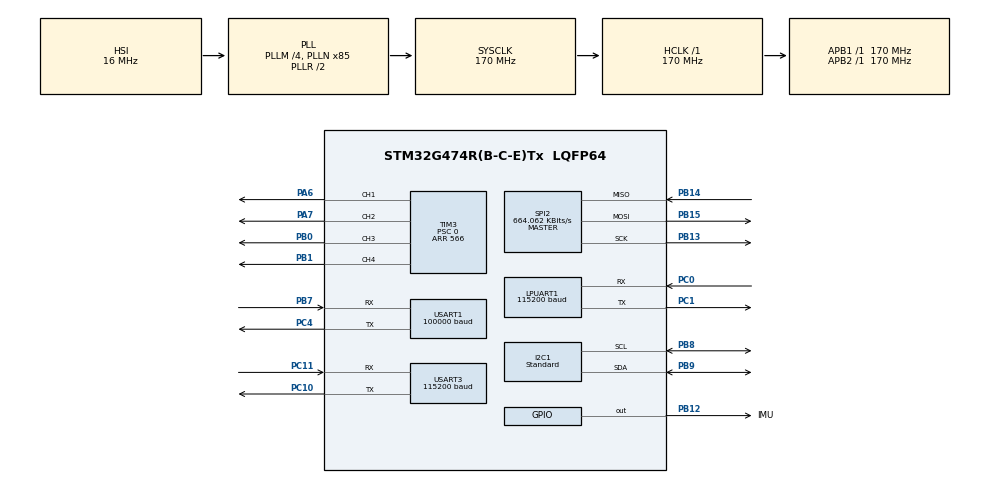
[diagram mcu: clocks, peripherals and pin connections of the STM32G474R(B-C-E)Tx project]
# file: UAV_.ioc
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Dma.Request0=TIM3_UP
Dma.TIM3_UP.0.Direction=DMA_MEMORY_TO_PERIPH
Dma.TIM3_UP.0.EventEnable=DISABLE
Dma.TIM3_UP.0.Instance=DMA1_Channel1
Dma.TIM3_UP.0.MemDataAlignment=DMA_MDATAALIGN_HALFWORD
Dma.TIM3_UP.0.MemInc=DMA_MINC_ENABLE
Dma.TIM3_UP.0.Mode=DMA_NORMAL
Dma.TIM3_UP.0.PeriphDataAlignment=DMA_PDATAALIGN_HALFWORD
Dma.TIM3_UP.0.PeriphInc=DMA_PINC_DISABLE
Dma.TIM3_UP.0.Polarity=HAL_DMAMUX_REQ_GEN_RISING
Dma.TIM3_UP.0.Priority=DMA_PRIORITY_VERY_HIGH
Dma.TIM3_UP.0.RequestNumber=1
Dma.TIM3_UP.0.SignalID=NONE
Dma.TIM3_UP.0.SyncEnable=DISABLE
Dma.TIM3_UP.0.SyncPolarity=HAL_DMAMUX_SYNC_NO_EVENT
Dma.TIM3_UP.0.SyncRequestNumber=1
Dma.TIM3_UP.0.SyncSignalID=NONE
I2C1.I2C_Speed_Mode=I2C_Standard
I2C1.Timing=0x40B285C2
LPUART1.BaudRate=115200
Mcu.Family=STM32G4
Mcu.Name=STM32G474R(B-C-E)Tx
Mcu.Package=LQFP64
NUCLEO-G474RE.BUTTON=1
NUCLEO-G474RE.LD2=true
NUCLEO-G474RE.VCP=false
NVIC.DMA1_Channel1_IRQn=true\:0\:0\:false\:false\:true\:false\:true\:true
NVIC.EXTI15_10_IRQn=true\:0\:0\:false\:false\:true\:false\:true\:true
NVIC.I2C1_ER_IRQn=true\:4\:0\:false\:false\:true\:true\:true\:true
NVIC.I2C1_EV_IRQn=true\:4\:0\:false\:false\:true\:true\:true\:true
NVIC.LPUART1_IRQn=true\:6\:0\:false\:false\:true\:true\:true\:true
NVIC.PriorityGroup=NVIC_PRIORITYGROUP_4
NVIC.TIM3_IRQn=true\:0\:0\:false\:false\:true\:true\:true\:true
NVIC.USART1_IRQn=true\:2\:0\:false\:false\:true\:true\:true\:true
NVIC.USART3_IRQn=true\:3\:0\:false\:false\:true\:true\:true\:true
PA13.Mode=Serial_Wire
PA13.Signal=SYS_JTMS-SWDIO
PA14.Mode=Serial_Wire
PA14.Signal=SYS_JTCK-SWCLK
PC1.Mode=Asynchronous
PC1.Signal=LPUART1_TX
PC0.Mode=Asynchronous
PC0.Signal=LPUART1_RX
PA7.Signal=S_TIM3_CH2
PA6.Signal=S_TIM3_CH1
PB0.Signal=S_TIM3_CH3
PB1.Signal=S_TIM3_CH4
PB12.GPIO_Label=IMU
PB12.GPIO_Speed=GPIO_SPEED_FREQ_VERY_HIGH
PB12.PinState=GPIO_PIN_SET
PB12.Signal=GPIO_Output
PB13.Mode=Full_Duplex_Master
PB13.Signal=SPI2_SCK
PB14.Mode=Full_Duplex_Master
PB14.Signal=SPI2_MISO
PB15.Mode=Full_Duplex_Master
PB15.Signal=SPI2_MOSI
PB7.Mode=Asynchronous
PB7.Signal=USART1_RX
PB8-BOOT0.Mode=I2C
PB8-BOOT0.Signal=I2C1_SCL
PB9.Mode=I2C
PB9.Signal=I2C1_SDA
PC4.Mode=Asynchronous
PC4.Signal=USART1_TX
PC10.Mode=Asynchronous
PC10.Signal=USART3_TX
PC11.Mode=Asynchronous
PC11.Signal=USART3_RX
ProjectManager.HeapSize=0x200
ProjectManager.StackSize=0x400
ProjectManager.TargetToolchain=STM32CubeIDE
RCC.ADC12Freq_Value=170000000
RCC.ADC345Freq_Value=170000000
RCC.AHBFreq_Value=170000000
RCC.APB1Freq_Value=170000000
RCC.APB1TimFreq_Value=170000000
RCC.APB2Freq_Value=170000000
RCC.APB2TimFreq_Value=170000000
RCC.CortexFreq_Value=170000000
RCC.EXTERNAL_CLOCK_VALUE=12288000
RCC.HCLKFreq_Value=170000000
RCC.HSE_VALUE=24000000
RCC.HSI48_VALUE=48000000
RCC.HSI_VALUE=16000000
RCC.LSE_VALUE=32768
RCC.PLLM=RCC_PLLM_DIV4
RCC.PLLN=85
RCC.RTCClockSelection=RCC_RTCCLKSOURCE_LSE
RCC.SYSCLKFreq_VALUE=170000000
RCC.SYSCLKSource=RCC_SYSCLKSOURCE_PLLCLK
RCC.USBFreq_Value=170000000
RCC.VCOOutputFreq_Value=340000000
SH.S_TIM3_CH1.0=TIM3_CH1,PWM Generation1 CH1
SH.S_TIM3_CH2.0=TIM3_CH2,PWM Generation2 CH2
SH.S_TIM3_CH3.0=TIM3_CH3,PWM Generation3 CH3
SH.S_TIM3_CH4.0=TIM3_CH4,PWM Generation4 CH4
SPI2.BaudRatePrescaler=SPI_BAUDRATEPRESCALER_256
SPI2.CLKPhase=SPI_PHASE_2EDGE
SPI2.CLKPolarity=SPI_POLARITY_HIGH
SPI2.CalculateBaudRate=664.062 KBits/s
SPI2.DataSize=SPI_DATASIZE_8BIT
SPI2.Direction=SPI_DIRECTION_2LINES
SPI2.Mode=SPI_MODE_MASTER
SPI2.VirtualType=VM_MASTER
TIM3.Channel-PWM\ Generation1\ CH1=TIM_CHANNEL_1
TIM3.Channel-PWM\ Generation2\ CH2=TIM_CHANNEL_2
TIM3.Channel-PWM\ Generation3\ CH3=TIM_CHANNEL_3
TIM3.Channel-PWM\ Generation4\ CH4=TIM_CHANNEL_4
TIM3.PeriodNoDither=566
TIM3.Prescaler=0
USART1.BaudRate=100000
USART1.WordLength=WORDLENGTH_9B
USART1.Parity=PARITY_EVEN
USART1.StopBits=STOPBITS_2
USART1.Mode=MODE_RX
USART1.OverSampling=UART_OVERSAMPLING_16
USART1.HwFlowCtl-Asynchronous=UART_HWCONTROL_NONE
USART1.RxPinLevelInvertParam=ADVFEATURE_RXINV_ENABLE
USART1.VirtualMode-Asynchronous=VM_ASYNC
USART3.BaudRate=115200
USART3.HwFlowCtl-Asynchronous=UART_HWCONTROL_NONE
USART3.Mode=MODE_TX_RX
USART3.OverSampling=UART_OVERSAMPLING_16
USART3.Parity=PARITY_NONE
USART3.StopBits=STOPBITS_1
USART3.VirtualMode-Asynchronous=VM_ASYNC
USART3.WordLength=WORDLENGTH_8B
VP_NUCLEO-G474RE_VS_BSP_COMMON.Mode=COMMON
VP_SYS_VS_DBSignals.Mode=DisableDeadBatterySignals
VP_TIM3_VS_ClockSourceINT.Mode=Internal
board=NUCLEO-G474RE

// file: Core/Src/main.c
/* USER CODE BEGIN Header */
/**
  ******************************************************************************
  * @file           : main.c
  * @brief          : Main program body - Dự án UAV DATN (Khối 1/3)
  ******************************************************************************
  */
/* USER CODE END Header */
#include "main.h"

/* USER CODE BEGIN Includes */
#include "uav_test.h"
/* USER CODE END Includes */

I2C_HandleTypeDef hi2c1;

UART_HandleTypeDef hlpuart1;
UART_HandleTypeDef huart1;
UART_HandleTypeDef huart3;

SPI_HandleTypeDef hspi2;

TIM_HandleTypeDef htim3;
DMA_HandleTypeDef hdma_tim3_up;

void SystemClock_Config(void);
static void MX_GPIO_Init(void);
static void MX_DMA_Init(void);
static void MX_TIM3_Init(void);
static void MX_USART1_UART_Init(void);
static void MX_USART3_UART_Init(void);
static void MX_LPUART1_UART_Init(void);
static void MX_SPI2_Init(void);
static void MX_I2C1_Init(void);

int main(void)
{

  /* MCU Configuration--------------------------------------------------------*/

  /* Reset of all peripherals, Initializes the Flash interface and the Systick. */
  HAL_Init();

  /* Configure the system clock */
  SystemClock_Config();

  /* Initialize all configured peripherals */
  MX_GPIO_Init();
  MX_DMA_Init();
  MX_TIM3_Init();
  MX_USART1_UART_Init();
  MX_USART3_UART_Init();
  MX_LPUART1_UART_Init();
  MX_SPI2_Init();
  MX_I2C1_Init();
  /* USER CODE BEGIN 2 */
  /* Initialize board indicators before enabling the TIM3 DShot output channels. */
  BSP_LED_Init(LED_GREEN);
  BSP_PB_Init(BUTTON_USER, BUTTON_MODE_EXTI);

  uav_test_init();
  /* USER CODE END 2 */

  /* Infinite loop */
  while (1)
  {

    /* USER CODE BEGIN 3 */
    /* Process SBUS, transmit DShot motor commands, and service IMU/barometer. */
    uav_test_loop();
  }
  /* USER CODE END 3 */
}

void SystemClock_Config(void)
{
  RCC_OscInitTypeDef RCC_OscInitStruct = {0};
  RCC_ClkInitTypeDef RCC_ClkInitStruct = {0};

  /** Configure the main internal regulator output voltage
  */
  HAL_PWREx_ControlVoltageScaling(PWR_REGULATOR_VOLTAGE_SCALE1_BOOST);

  /** Initializes the RCC Oscillators according to the specified parameters
  * in the RCC_OscInitTypeDef structure.
  */
  RCC_OscInitStruct.OscillatorType = RCC_OSCILLATORTYPE_HSI;
  RCC_OscInitStruct.HSIState = RCC_HSI_ON;
  RCC_OscInitStruct.HSICalibrationValue = RCC_HSICALIBRATION_DEFAULT;
  RCC_OscInitStruct.PLL.PLLState = RCC_PLL_ON;
  RCC_OscInitStruct.PLL.PLLSource = RCC_PLLSOURCE_HSI;
  RCC_OscInitStruct.PLL.PLLM = RCC_PLLM_DIV4;
  RCC_OscInitStruct.PLL.PLLN = 85;
  RCC_OscInitStruct.PLL.PLLP = RCC_PLLP_DIV2;
  RCC_OscInitStruct.PLL.PLLQ = RCC_PLLQ_DIV2;
  RCC_OscInitStruct.PLL.PLLR = RCC_PLLR_DIV2;
  if (HAL_RCC_OscConfig(&RCC_OscInitStruct) != HAL_OK)
  {
    Error_Handler();
  }

  /** Initializes the CPU, AHB and APB buses clocks
  */
  RCC_ClkInitStruct.ClockType = RCC_CLOCKTYPE_HCLK|RCC_CLOCKTYPE_SYSCLK
                              |RCC_CLOCKTYPE_PCLK1|RCC_CLOCKTYPE_PCLK2;
  RCC_ClkInitStruct.SYSCLKSource = RCC_SYSCLKSOURCE_PLLCLK;
  RCC_ClkInitStruct.AHBCLKDivider = RCC_SYSCLK_DIV1;
  RCC_ClkInitStruct.APB1CLKDivider = RCC_HCLK_DIV1;
  RCC_ClkInitStruct.APB2CLKDivider = RCC_HCLK_DIV1;

  if (HAL_RCC_ClockConfig(&RCC_ClkInitStruct, FLASH_LATENCY_4) != HAL_OK)
  {
    Error_Handler();
  }
}

static void MX_I2C1_Init(void)
{

  hi2c1.Instance = I2C1;
  hi2c1.Init.Timing = 0x40B285C2;
  hi2c1.Init.OwnAddress1 = 0;
  hi2c1.Init.AddressingMode = I2C_ADDRESSINGMODE_7BIT;
  hi2c1.Init.DualAddressMode = I2C_DUALADDRESS_DISABLE;
  hi2c1.Init.OwnAddress2 = 0;
  hi2c1.Init.OwnAddress2Masks = I2C_OA2_NOMASK;
  hi2c1.Init.GeneralCallMode = I2C_GENERALCALL_DISABLE;
  hi2c1.Init.NoStretchMode = I2C_NOSTRETCH_DISABLE;
  if (HAL_I2C_Init(&hi2c1) != HAL_OK)
  {
    Error_Handler();
  }

  /** Configure Analogue filter
  */
  if (HAL_I2CEx_ConfigAnalogFilter(&hi2c1, I2C_ANALOGFILTER_ENABLE) != HAL_OK)
  {
    Error_Handler();
  }

  /** Configure Digital filter
  */
  if (HAL_I2CEx_ConfigDigitalFilter(&hi2c1, 0) != HAL_OK)
  {
    Error_Handler();
  }

}

static void MX_LPUART1_UART_Init(void)
{

  hlpuart1.Instance = LPUART1;
  hlpuart1.Init.BaudRate = 115200;
  hlpuart1.Init.WordLength = UART_WORDLENGTH_8B;
  hlpuart1.Init.StopBits = UART_STOPBITS_1;
  hlpuart1.Init.Parity = UART_PARITY_NONE;
  hlpuart1.Init.Mode = UART_MODE_TX_RX;
  hlpuart1.Init.HwFlowCtl = UART_HWCONTROL_NONE;
  hlpuart1.Init.OneBitSampling = UART_ONE_BIT_SAMPLE_DISABLE;
  hlpuart1.Init.ClockPrescaler = UART_PRESCALER_DIV1;
  hlpuart1.AdvancedInit.AdvFeatureInit = UART_ADVFEATURE_NO_INIT;
  if (HAL_UART_Init(&hlpuart1) != HAL_OK)
  {
    Error_Handler();
  }
  if (HAL_UARTEx_SetTxFifoThreshold(&hlpuart1, UART_TXFIFO_THRESHOLD_1_8) != HAL_OK)
  {
    Error_Handler();
  }
  if (HAL_UARTEx_SetRxFifoThreshold(&hlpuart1, UART_RXFIFO_THRESHOLD_1_8) != HAL_OK)
  {
    Error_Handler();
  }
  if (HAL_UARTEx_DisableFifoMode(&hlpuart1) != HAL_OK)
  {
    Error_Handler();
  }

}

static void MX_USART1_UART_Init(void)
{

  huart1.Instance = USART1;
  /* SBUS: 100 kbit/s, 8 data bits, even parity, 2 stop bits (8E2).
     9-bit word length + parity gives 8 payload bits on STM32 USART. */
  huart1.Init.BaudRate = 100000;
  huart1.Init.WordLength = UART_WORDLENGTH_9B;
  huart1.Init.StopBits = UART_STOPBITS_2;
  huart1.Init.Parity = UART_PARITY_EVEN;
  huart1.Init.Mode = UART_MODE_RX;
  huart1.Init.HwFlowCtl = UART_HWCONTROL_NONE;
  huart1.Init.OverSampling = UART_OVERSAMPLING_16;
  huart1.Init.OneBitSampling = UART_ONE_BIT_SAMPLE_DISABLE;
  huart1.Init.ClockPrescaler = UART_PRESCALER_DIV1;
  huart1.AdvancedInit.AdvFeatureInit = UART_ADVFEATURE_RXINVERT_INIT;
  huart1.AdvancedInit.RxPinLevelInvert = UART_ADVFEATURE_RXINV_ENABLE;
  if (HAL_UART_Init(&huart1) != HAL_OK)
  {
    Error_Handler();
  }
  if (HAL_UARTEx_SetTxFifoThreshold(&huart1, UART_TXFIFO_THRESHOLD_1_8) != HAL_OK)
  {
    Error_Handler();
  }
  if (HAL_UARTEx_SetRxFifoThreshold(&huart1, UART_RXFIFO_THRESHOLD_1_8) != HAL_OK)
  {
    Error_Handler();
  }
  if (HAL_UARTEx_DisableFifoMode(&huart1) != HAL_OK)
  {
    Error_Handler();
  }

}

static void MX_USART3_UART_Init(void)
{
  huart3.Instance = USART3;
  huart3.Init.BaudRate = 115200;
  huart3.Init.WordLength = UART_WORDLENGTH_8B;
  huart3.Init.StopBits = UART_STOPBITS_1;
  huart3.Init.Parity = UART_PARITY_NONE;
  huart3.Init.Mode = UART_MODE_TX_RX;
  huart3.Init.HwFlowCtl = UART_HWCONTROL_NONE;
  huart3.Init.OverSampling = UART_OVERSAMPLING_16;
  huart3.Init.OneBitSampling = UART_ONE_BIT_SAMPLE_DISABLE;
  huart3.Init.ClockPrescaler = UART_PRESCALER_DIV1;
  huart3.AdvancedInit.AdvFeatureInit = UART_ADVFEATURE_NO_INIT;

  if (HAL_UART_Init(&huart3) != HAL_OK)
  {
    Error_Handler();
  }

  if (HAL_UARTEx_SetTxFifoThreshold(&huart3, UART_TXFIFO_THRESHOLD_1_8) != HAL_OK)
  {
    Error_Handler();
  }

  if (HAL_UARTEx_SetRxFifoThreshold(&huart3, UART_RXFIFO_THRESHOLD_1_8) != HAL_OK)
  {
    Error_Handler();
  }

  if (HAL_UARTEx_DisableFifoMode(&huart3) != HAL_OK)
  {
    Error_Handler();
  }
}

static void MX_SPI2_Init(void)
{

  /* SPI2 parameter configuration*/
  hspi2.Instance = SPI2;
  hspi2.Init.Mode = SPI_MODE_MASTER;
  hspi2.Init.Direction = SPI_DIRECTION_2LINES;
  hspi2.Init.DataSize = SPI_DATASIZE_8BIT;
  hspi2.Init.CLKPolarity = SPI_POLARITY_HIGH;
  hspi2.Init.CLKPhase = SPI_PHASE_2EDGE;
  hspi2.Init.NSS = SPI_NSS_SOFT;
  hspi2.Init.BaudRatePrescaler = SPI_BAUDRATEPRESCALER_256;
  hspi2.Init.FirstBit = SPI_FIRSTBIT_MSB;
  hspi2.Init.TIMode = SPI_TIMODE_DISABLE;
  hspi2.Init.CRCCalculation = SPI_CRCCALCULATION_DISABLE;
  hspi2.Init.CRCPolynomial = 7;
  hspi2.Init.CRCLength = SPI_CRC_LENGTH_DATASIZE;
  hspi2.Init.NSSPMode = SPI_NSS_PULSE_DISABLE;
  if (HAL_SPI_Init(&hspi2) != HAL_OK)
  {
    Error_Handler();
  }

}

static void MX_TIM3_Init(void)
{

  TIM_ClockConfigTypeDef sClockSourceConfig = {0};
  TIM_MasterConfigTypeDef sMasterConfig = {0};
  TIM_OC_InitTypeDef sConfigOC = {0};

  htim3.Instance = TIM3;
  /* 170 MHz timer clock / 567 ticks = approximately 300 kbit/s DShot. */
  htim3.Init.Prescaler = 0;
  htim3.Init.CounterMode = TIM_COUNTERMODE_UP;
  htim3.Init.Period = 566;
  htim3.Init.ClockDivision = TIM_CLOCKDIVISION_DIV1;
  htim3.Init.AutoReloadPreload = TIM_AUTORELOAD_PRELOAD_DISABLE;
  if (HAL_TIM_Base_Init(&htim3) != HAL_OK)
  {
    Error_Handler();
  }
  sClockSourceConfig.ClockSource = TIM_CLOCKSOURCE_INTERNAL;
  if (HAL_TIM_ConfigClockSource(&htim3, &sClockSourceConfig) != HAL_OK)
  {
    Error_Handler();
  }
  if (HAL_TIM_PWM_Init(&htim3) != HAL_OK)
  {
    Error_Handler();
  }
  sMasterConfig.MasterOutputTrigger = TIM_TRGO_RESET;
  sMasterConfig.MasterSlaveMode = TIM_MASTERSLAVEMODE_DISABLE;
  if (HAL_TIMEx_MasterConfigSynchronization(&htim3, &sMasterConfig) != HAL_OK)
  {
    Error_Handler();
  }
  sConfigOC.OCMode = TIM_OCMODE_PWM1;
  sConfigOC.Pulse = 0;
  sConfigOC.OCPolarity = TIM_OCPOLARITY_HIGH;
  sConfigOC.OCFastMode = TIM_OCFAST_DISABLE;
  if (HAL_TIM_PWM_ConfigChannel(&htim3, &sConfigOC, TIM_CHANNEL_1) != HAL_OK)
  {
    Error_Handler();
  }
  if (HAL_TIM_PWM_ConfigChannel(&htim3, &sConfigOC, TIM_CHANNEL_2) != HAL_OK)
  {
    Error_Handler();
  }
  if (HAL_TIM_PWM_ConfigChannel(&htim3, &sConfigOC, TIM_CHANNEL_3) != HAL_OK)
  {
    Error_Handler();
  }
  if (HAL_TIM_PWM_ConfigChannel(&htim3, &sConfigOC, TIM_CHANNEL_4) != HAL_OK)
  {
    Error_Handler();
  }
  HAL_TIM_MspPostInit(&htim3);

}

static void MX_DMA_Init(void)
{

  /* DMA controller clock enable */
  __HAL_RCC_DMAMUX1_CLK_ENABLE();
  __HAL_RCC_DMA1_CLK_ENABLE();

  /* DMA interrupt init */
  /* DMA1_Channel1_IRQn interrupt configuration */
  HAL_NVIC_SetPriority(DMA1_Channel1_IRQn, 0, 0);
  HAL_NVIC_EnableIRQ(DMA1_Channel1_IRQn);

}

static void MX_GPIO_Init(void)
{
  GPIO_InitTypeDef GPIO_InitStruct = {0};

  /* GPIO Ports Clock Enable */
  __HAL_RCC_GPIOA_CLK_ENABLE();
  __HAL_RCC_GPIOC_CLK_ENABLE();
  __HAL_RCC_GPIOB_CLK_ENABLE();

  /*Configure GPIO pin Output Level */
  HAL_GPIO_WritePin(IMU_GPIO_Port, IMU_Pin, GPIO_PIN_SET);

  /*Configure GPIO pin : IMU_Pin */
  GPIO_InitStruct.Pin = IMU_Pin;
  GPIO_InitStruct.Mode = GPIO_MODE_OUTPUT_PP;
  GPIO_InitStruct.Pull = GPIO_NOPULL;
  GPIO_InitStruct.Speed = GPIO_SPEED_FREQ_VERY_HIGH;
  HAL_GPIO_Init(IMU_GPIO_Port, &GPIO_InitStruct);

}

void Error_Handler(void)
{
  __disable_irq();
  while (1)
  {
  }
}
